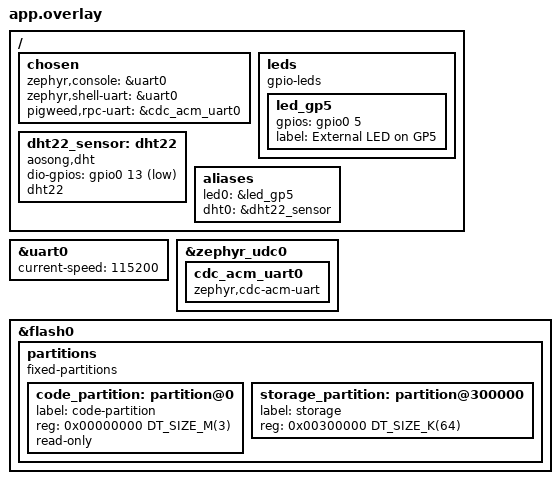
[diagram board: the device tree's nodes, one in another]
/ {
    chosen {
        zephyr,console = &uart0;
        zephyr,shell-uart = &uart0;
        pigweed,rpc-uart = &cdc_acm_uart0;
    };
    leds {
        compatible = "gpio-leds";
        led_gp5: led_gp5 {
            gpios = <&gpio0 5 GPIO_ACTIVE_HIGH>;
            label = "External LED on GP5";
        };
    };
    dht22_sensor: dht22 {
        compatible = "aosong,dht";
        status = "okay";
        dio-gpios = <&gpio0 13 (GPIO_PULL_UP | GPIO_ACTIVE_LOW)>;
        dht22;
    };
    aliases {
        led0 = &led_gp5;
        dht0 = &dht22_sensor;
    };
};

&uart0 {
    status = "okay";
    current-speed = <115200>;
};
&zephyr_udc0 {
	status = "okay";    
	cdc_acm_uart0: cdc_acm_uart0 {
		compatible = "zephyr,cdc-acm-uart";
		status = "okay";
	};
};
&flash0 {
    partitions {
        compatible = "fixed-partitions";
        #address-cells = <1>;
        #size-cells = <1>;

        code_partition: partition@0 {
            label = "code-partition";
            reg = <0x00000000 DT_SIZE_M(3)>;
            read-only;
        };

        storage_partition: partition@300000 {
            label = "storage";
            reg = <0x00300000 DT_SIZE_K(64)>;
        };
    };
};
